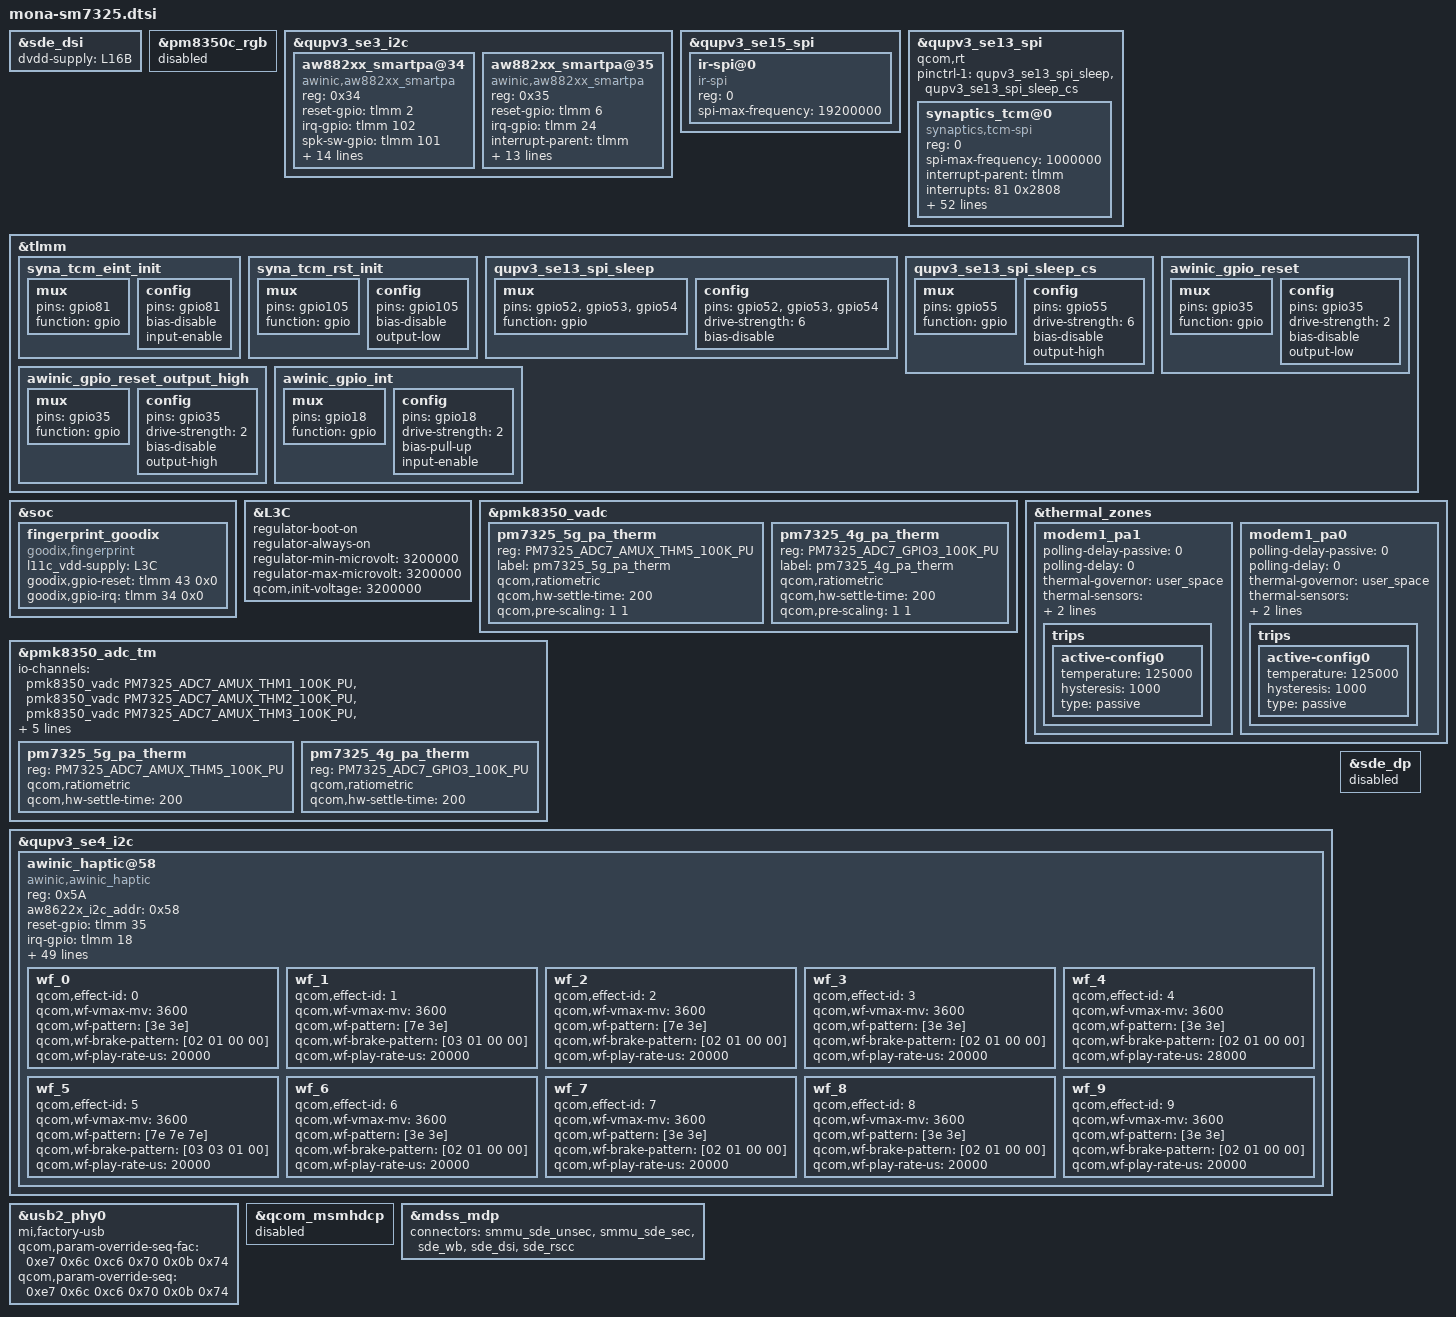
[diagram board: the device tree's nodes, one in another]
/*
this file is for attribution only of mona
And public attribution of xiaomi platforms
*/

#include "mona-pinctrl.dtsi"
#include "xiaomi-sm7325-common.dtsi"
#include "camera/mona-sm7325-camera-sensor.dtsi"
#include "mona-audio-overlay.dtsi"

&sde_dsi {
	dvdd-supply = <&L16B>;
};

&pm8350c_rgb {
	status = "disabled";
};

&qupv3_se3_i2c {
	status = "ok";

	/* TOP Smart PA */
	aw882xx_smartpa@34 {
		compatible = "awinic,aw882xx_smartpa";
		reg = <0x34>;
		reset-gpio = <&tlmm 2 0>;
		irq-gpio = <&tlmm 102 0>;
		spk-sw-gpio = <&tlmm 101 0>;
		interrupt-parent = <&tlmm>;
		interrupts = <102 0>;
		interrupt-names = "smartpa_irq";
		pinctrl-names = "default", "sleep";
		pinctrl-0 = <&top_smartpa_int_active>;
		pinctrl-1 = <&top_smartpa_int_suspend>;
		monitor-flag = <1>;
		dc-flag = <0>;
		aw-tx-topo-id = <0x1000ff01>;
		aw-rx-topo-id = <0x1000ff00>;
		aw-tx-port-id = <0x9001>;
		aw-rx-port-id = <0x9000>;
		aw-re-min = <4000>;
		aw-re-max= <9000>;
		aw-cali-mode = "aw_class";
		sound-channel = <0>;
		status = "ok";
	};

	/* BOT Smart PA */
	aw882xx_smartpa@35 {
		compatible = "awinic,aw882xx_smartpa";
		reg = <0x35>;
		reset-gpio = <&tlmm 6 0>;
		irq-gpio = <&tlmm 24 0>;
		interrupt-parent = <&tlmm>;
		interrupts = <24 0>;
		interrupt-names = "smartpa_irq";
		pinctrl-names = "default", "sleep";
		pinctrl-0 = <&bot_smartpa_int_active>;
		pinctrl-1 = <&bot_smartpa_int_suspend>;
		monitor-flag = <1>;
		dc-flag = <0>;
		aw-tx-topo-id = <0x1000ff01>;
		aw-rx-topo-id = <0x1000ff00>;
		aw-tx-port-id = <0x9001>;
		aw-rx-port-id = <0x9000>;
		aw-re-min = <4000>;
		aw-re-max= <9000>;
		aw-cali-mode = "aw_class";
		sound-channel = <1>;
		status = "ok";
	};
};

&qupv3_se15_spi {
	status = "ok";
	ir-spi@0 {
		compatible = "ir-spi";
		reg = <0>;
		spi-max-frequency = <19200000>;
		status = "ok";
	};
};

&qupv3_se13_spi {
	status = "ok";
	qcom,rt;
	pinctrl-1 = <&qupv3_se13_spi_sleep &qupv3_se13_spi_sleep_cs>;
	synaptics_tcm@0 {
		compatible = "synaptics,tcm-spi";
		reg = <0>;
		spi-max-frequency = <1000000>;
		interrupt-parent = <&tlmm>;
		interrupts = <81 0x2808>;
		synaptics,avdd-name = "avdd";
		avdd-supply = <&L7C>;
		synaptics,iovdd-name = "iovdd";
		iovdd-supply = <&L2C>;
		/*synaptics,bus-reg-name = "vdd";*/
		/*synaptics,pwr-reg-name = "avdd";*/
		synaptics,irq-gpio = <&tlmm 81 0x2808>;
		synaptics,reset-gpio = <&tlmm 105 0x00>;
		synaptics,irq-on-state = <0>;
		synaptics,spi-mode = <0>;
		synaptics,byte-delay-us = <0>;
		synaptics,block-delay-us = <0>;
		synaptics,power-delay-ms = <50>;
		synaptics,reset-delay-ms = <200>;
		synaptics,ubl-max-freq = <5000000>;
		synaptics,ubl-byte-delay-us = <20>;
		pinctrl-names = "default";
		pinctrl-0 = <&syna_tcm_eint_init &syna_tcm_rst_init>;
		synaptics,game-mode-array =
				<1 0 0 0 0>;  /* MAX MIN DEF SET GET	*/
		synaptics,active-mode-array =
				<1 0 0 0 0>;  /* MAX MIN DEF SET GET	*/
		synaptics,up-threshold-array =
				<3 0 3 3 3>;  /* MAX MIN DEF SET GET	*/
		synaptics,tolerance-array =
				<3 0 3 3 3>;  /* MAX MIN DEF SET GET	*/
		synaptics,edge-filter-array =
				<3 0 2 2 2>;  /* MAX MIN DEF SET GET	*/
		synaptics,panel-orien-array =
				<3 0 0 0 0>;  /* MAX MIN DEF SET GET	*/
		synaptics,report-rate-array =
				<3 0 0 0 0>;  /* MAX MIN DEF SET GET	*/
		synaptics,cornerfilter-area-step-array = <0 100 170 250>; /* step 0 to step 3 */
		synaptics,cornerzone-filter-hor1-array =
			/* B0:Type, B1:pos, B2:x0, B3:y0, B4:x1, B5:y1, B6:reserved, B7: reserved */
				<0 0 0 0 170 170 0 0>,
				<0 1 0 0 0 0 0 0>,
				<0 2 0 2229 170 2399 0 0>,
				<0 3 0 0 0 0 0 0>;
		synaptics,cornerzone-filter-hor2-array =
			/* B0:Type, B1:pos, B2:x0, B3:y0, B4:x1, B5:y1, B6:reserved, B7: reserved */
				<0 0 0 0 0 0 0 0>,
				<0 1 909 0 1079 170 0 0>,
				<0 2 0 0 0 0 0 0>,
				<0 3 909 2229 1079 2399 0 0>;
		synaptics,cornerzone-filter-ver-array =
			/* B0:Type, B1:pos, B2:x0, B3:y0, B4:x1, B5:y1, B6:reserved, B7: reserved */
				<0 0 0 0 0 0 0 0>,
				<0 1 0 0 0 0 0 0>,
				<0 2 0 2099 150 2399 0 0>,
				<0 3 929 2099 1079 2399 0 0>;
		synaptics,deadzone-filter-hor-array =
			/* B0:Type, B1:pos, B2:x0, B3:y0, B4:x1, B5:y1, B6:reserved, B7: reserved */
				<2 0 0 0 1079 5 0 0>,
				<2 1 0 2394 1079 2399 0 0>,
				<2 2 0 0 0 0 0 0>,
				<2 3 0 0 0 0 0 0>;
		synaptics,deadzone-filter-ver-array =
			/* B0:Type, B1:pos, B2:x0, B3:y0, B4:x1, B5:y1, B6:reserved, B7: reserved */
				<2 0 0 0 0 0 0 0>,
				<2 1 0 0 0 0 0 0>,
				<2 2 0 0 5 2399 0 0>,
				<2 3 1074 0 1079 2399 0 0>;
		synaptics,edgezone-filter-hor-array =
			/* B0:Type, B1:pos, B2:x0, B3:y0, B4:x1, B5:y1, B6:reserved, B7: reserved */
				<1 0 0 0 1079 40 0 0>,
				<1 1 0 2359 1079 2399 0 0>,
				<1 2 0 0 40 2399 0 0>,
				<1 3 1039 0 1079 2399 0 0>;
		synaptics,edgezone-filter-ver-array =
			/* B0:Type, B1:pos, B2:x0, B3:y0, B4:x1, B5:y1, B6:reserved, B7: reserved */
				<1 0 0 0 0 0 0 0>,
				<1 1 0 0 0 0 0 0>,
				<1 2 0 0 40 2399 0 0>,
				<1 3 1039 0 1079 2399 0 0>;
		synaptics,panel-display-resolution = <1079 2399>;  /* X  Y*/
	};
};

&tlmm {
	syna_tcm_eint_init: syna_tcm_eint_init {
		mux {
			/* GPIO 81 Interrupt */
			pins = "gpio81";
			function = "gpio";
		};

		config {
			pins = "gpio81";
			bias-disable;
			input-enable;
		};
	};

	syna_tcm_rst_init: syna_tcm_rst_init {
		mux {
			/* GPIO 105 Interrupt */
			pins = "gpio105";
			function = "gpio";
		};

		config {
			pins = "gpio105";
			bias-disable;
			output-low;
		};
	};

	qupv3_se13_spi_sleep: qupv3_se13_spi_sleep {
		mux {
			pins = "gpio52", "gpio53",
					"gpio54";
			function = "gpio";
		};

		config {
			pins = "gpio52", "gpio53",
					"gpio54";
			drive-strength = <6>;
			bias-disable;
		};
	};

	qupv3_se13_spi_sleep_cs: qupv3_se13_spi_sleep_cs {
		mux {
			pins = "gpio55";
			function = "gpio";
		};

		config {
			pins = "gpio55";
			drive-strength = <6>;
			bias-disable;
			output-high;
		};
	};
};

&soc {
	fingerprint_goodix {
		compatible = "goodix,fingerprint";
		l11c_vdd-supply = <&L3C>;
		goodix,gpio-reset = <&tlmm 43 0x0>;
		goodix,gpio-irq = <&tlmm 34 0x0>;
		status = "ok";
	};
};

&L3C {
	regulator-boot-on;
	regulator-always-on;
	regulator-min-microvolt = <3200000>;
	regulator-max-microvolt = <3200000>;
	qcom,init-voltage = <3200000>;
};


&pmk8350_vadc {
	pm7325_5g_pa_therm {
		reg = <PM7325_ADC7_AMUX_THM5_100K_PU>;
		label = "pm7325_5g_pa_therm";
		qcom,ratiometric;
		qcom,hw-settle-time = <200>;
		qcom,pre-scaling = <1 1>;
        };
	pm7325_4g_pa_therm {
		reg = <PM7325_ADC7_GPIO3_100K_PU>;
                label = "pm7325_4g_pa_therm";
		qcom,ratiometric;
		qcom,hw-settle-time = <200>;
		qcom,pre-scaling = <1 1>;
	};
};

&pmk8350_adc_tm {
	io-channels = <&pmk8350_vadc PM7325_ADC7_AMUX_THM1_100K_PU>,
			<&pmk8350_vadc PM7325_ADC7_AMUX_THM2_100K_PU>,
			<&pmk8350_vadc PM7325_ADC7_AMUX_THM3_100K_PU>,
			<&pmk8350_vadc PM7325_ADC7_AMUX_THM4_100K_PU>,
			<&pmk8350_vadc PMK8350_ADC7_AMUX_THM1_100K_PU>,
                        <&pmk8350_vadc PM7325B_ADC7_GPIO2_100K_PU>,
                        <&pmk8350_vadc PM7325_ADC7_AMUX_THM5_100K_PU>,
                        <&pmk8350_vadc PM7325_ADC7_GPIO3_100K_PU>;
	pm7325_5g_pa_therm {
		reg = <PM7325_ADC7_AMUX_THM5_100K_PU>;
		qcom,ratiometric;
		qcom,hw-settle-time = <200>;
	};
	pm7325_4g_pa_therm {
		reg = <PM7325_ADC7_GPIO3_100K_PU>;
		qcom,ratiometric;
		qcom,hw-settle-time = <200>;
	};
};

&thermal_zones {
	modem1_pa1 {
		polling-delay-passive = <0>;
		polling-delay = <0>;
		thermal-governor = "user_space";
		thermal-sensors = <&pmk8350_adc_tm PM7325_ADC7_AMUX_THM5_100K_PU>;
		wake-capable-sensor;
		trips {
			active-config0 {
				temperature = <125000>;
				hysteresis = <1000>;
				type = "passive";
			};
		};
	};

	modem1_pa0 {
		polling-delay-passive = <0>;
		polling-delay = <0>;
		thermal-governor = "user_space";
		thermal-sensors = <&pmk8350_adc_tm PM7325_ADC7_GPIO3_100K_PU>;
		wake-capable-sensor;
		trips {
			active-config0 {
				temperature = <125000>;
				hysteresis = <1000>;
				type = "passive";
			};
		};
	};
};
&qupv3_se4_i2c {
     status = "ok";
     awinic_haptic@58 {
		compatible = "awinic,awinic_haptic";
		reg = <0x5A>;
		aw8622x_i2c_addr = < 0x58 >;
		reset-gpio = <&tlmm 35 0>;
		irq-gpio = <&tlmm 18 0>;
		pinctrl-names = "awinic_reset_reset","awinic_reset_active","awinic_interrupt_active";
		pinctrl-0 = <&awinic_gpio_reset>;
		pinctrl-1 = <&awinic_gpio_reset_output_high>;
		pinctrl-2 = <&awinic_gpio_int>;
		/*---------------------aw8624_dts_info---------------------*/
		aw8624_vib_f0_pre = < 2050 >;
		aw8624_vib_f0_cali_percen = < 7 >;
		aw8624_vib_cont_drv_lev = < 106 >;
		aw8624_vib_cont_drv_lvl_ov = < 155 >;
		aw8624_vib_cont_td = < 0xF06C >;
		aw8624_vib_cont_zc_thr = < 0x08F8 >;
		aw8624_vib_cont_num_brk = < 3 >;
		aw8624_vib_f0_coeff = < 260 >; /*Don't modify it*/
		aw8624_vib_duration_time = < 15 60 0 0 0 >;
		aw8624_vib_brake_ram_config = < 1 1 90 60 20 3 1 3 1 1 90 60 30 5 1 3 0 0 50 40 25 0 5 3 >;
		aw8624_vib_brake_cont_config = < 1 1 90 42 20 5 2 2 0 0 0 0 0 0 0 0 0 0 0 0 0 0 0 0 >;
		aw8624_vib_f0_trace_parameter = < 9 5 1 15 >;
		aw8624_vib_bemf_config = < 0 8 3 0xf8 >;
		aw8624_vib_sw_brake = < 0x2c >;
		aw8624_vib_wavseq = < 0 1 1 2 0 0 0 0 0 0 0 0 0 0 0 0 >; /*wavseq1-seq8 0x07-0x0E*/
		aw8624_vib_wavloop = < 0 6 1 15 0 0 0 0 0 0>;/*loop1-mainloog 0x0f-0x13*/
		aw8624_vib_td_brake = < 42720 42720 42720 >; /*level0 level1 level2*/
		aw8624_vib_tset = < 0x11 >;
		aw8624_vib_func_parameter1 = < 1 >;
		aw8624_vib_gain_flag = < 1 >;
		aw8624_vib_r_spare = < 0x68 >;
		aw8624_vib_bstdbg = < 0x30 0xeb 0xd4 0 0 0 >;
		/*---------------------aw8622x_dts_info---------------------*/
		aw8622x_vib_mode = < 0 >; /* mode: RAM mode->0; CONT mode->1 */
		aw8622x_vib_f0_pre = < 2050 >;
		aw8622x_vib_f0_cali_percen = < 7 >;
		aw8622x_vib_cont_drv1_lvl = < 0x7F >;
		aw8622x_vib_cont_drv2_lvl = < 0x36 >;
		aw8622x_vib_cont_brk_time = < 0x06 >;
		aw8622x_vib_cont_tset = < 0x06 >;
		aw8622x_vib_cont_bemf_set = < 0x02 >;
		aw8622x_vib_cont_drv_width = < 0x6A >;
		aw8622x_vib_cont_wait_num = < 0x06 >;
		aw8622x_vib_cont_brk_gain = < 0x08 >;
		aw8622x_vib_cont_drv1_time = < 0x04 >;
		aw8622x_vib_cont_drv2_time = < 0x14 >;
		aw8622x_vib_cont_track_margin = < 0x12 >;
		aw8622x_vib_sine_array = < 0x05 0xB2 0xFF 0xEF >; /* SIN_H SIN_L COS_H COS_L*/
		aw8622x_vib_d2s_gain = < 0x05 >;
		aw8622x_vib_prctmode = < 0x2D 0x3E 0x3F >;
		/*---------------------common_dts_info---------------------*/
		vib_effect_id_boundary = < 10 >;
		vib_effect_max = < 170 >;
		vib_rtp_time = < 20 20 20 20 20 20 20 20 20 30
				 40 50 60 70 80 90 100 110 120 130
				 140 150 160 170 180 190 200 210 220 230
				 240 250 260 270 280 290 300 310 320 330
				 20 20 20 20 20 20 20 20 20 20
				 20 20 20 20 20 20 20 20 20 20
				 20 20 20 20 20 20 20 20 20 20
				 20 20 20 20 20 20 20 20 20 20
				 20 20 20 20 20 20 20 20 20 20
				 20 20 20 20 20 20 20 20 20 20
				 20 20 20 20 20 20 20 20 20 20
				 20 20 20 20 20 20 20 20 20 20
				 20 20 20 20 20 20 20 20 20 20
				 20 20 20 20 20 20 20 20 20 20
				 20 20 20 20 20 20 20 20 20 20
				 20 20 20 20 20 20 20 20 20 20
				 20 20 20 20 20 20 20 20 20 20
				 20 20 20 20 20 >;
		status = "okay";
		wf_0 {
			//CLICK
			qcom,effect-id = <0>;
			qcom,wf-vmax-mv = <3600>;
			qcom,wf-pattern = [3e 3e];
			qcom,wf-brake-pattern = [02 01 00 00];
			qcom,wf-play-rate-us = <20000>;
		};
		wf_1 {
			//DOUBLE CLICK
			qcom,effect-id = <1>;
			qcom,wf-vmax-mv = <3600>;
			qcom,wf-pattern = [7e 3e];
			qcom,wf-brake-pattern = [03 01 00 00];
			qcom,wf-play-rate-us = <20000>;
		};
		wf_2 {
			//TICK
			qcom,effect-id = <2>;
			qcom,wf-vmax-mv = <3600>;
			qcom,wf-pattern = [7e 3e];
			qcom,wf-brake-pattern = [02 01 00 00];
			qcom,wf-play-rate-us = <20000>;
		};
		wf_3 {
			//THUD
			qcom,effect-id = <3>;
			qcom,wf-vmax-mv = <3600>;
			qcom,wf-pattern = [3e 3e];
			qcom,wf-brake-pattern = [02 01 00 00];
			qcom,wf-play-rate-us = <20000>;
		};
		wf_4 {
			//POP
			qcom,effect-id = <4>;
			qcom,wf-vmax-mv = <3600>;
			qcom,wf-pattern = [3e 3e];
			qcom,wf-brake-pattern = [02 01 00 00];
			qcom,wf-play-rate-us = <28000>;
		};
		wf_5 {
			//HEAVY CLICK
			qcom,effect-id = <5>;
			qcom,wf-vmax-mv = <3600>;
			qcom,wf-pattern = [7e 7e 7e];
			qcom,wf-brake-pattern = [03 03 01 00];
			qcom,wf-play-rate-us = <20000>;
		};
		wf_6 {
			//id 6
			qcom,effect-id = <6>;
			qcom,wf-vmax-mv = <3600>;
			qcom,wf-pattern = [3e 3e];
			qcom,wf-brake-pattern = [02 01 00 00];
			qcom,wf-play-rate-us = <20000>;
		};
		wf_7 {
			//id 7
			qcom,effect-id = <7>;
			qcom,wf-vmax-mv = <3600>;
			qcom,wf-pattern = [3e 3e];
			qcom,wf-brake-pattern = [02 01 00 00];
			qcom,wf-play-rate-us = <20000>;
		};
		wf_8 {
			//id 8
			qcom,effect-id = <8>;
			qcom,wf-vmax-mv = <3600>;
			qcom,wf-pattern = [3e 3e];
			qcom,wf-brake-pattern = [02 01 00 00];
			qcom,wf-play-rate-us = <20000>;
		};
		wf_9 {
			//id 9
			qcom,effect-id = <9>;
			qcom,wf-vmax-mv = <3600>;
			qcom,wf-pattern = [3e 3e];
			qcom,wf-brake-pattern = [02 01 00 00];
			qcom,wf-play-rate-us = <20000>;
		};
     };
};
&tlmm {
	/* AW86224_RESET_N */
	awinic_gpio_reset: awinic_gpio_reset {
		mux {
			pins = "gpio35";
		        function = "gpio";
		};

		config {
			pins = "gpio35";
			drive-strength = <2>;
			bias-disable;
			output-low;
		};
	};
	/* AW8624_RESET_N, state device active*/
	awinic_gpio_reset_output_high: awinic_gpio_reset_output_high {
		mux {
			pins = "gpio35";
			function = "gpio";
		};

		config {
			pins = "gpio35";
			drive-strength = <2>;
			bias-disable;
			output-high;
		};
	};
	/* AW86224_INTERRUPT_N */
	awinic_gpio_int: awinic_gpio_int {
		mux {
			pins = "gpio18";
			function = "gpio";
		};

		config {
			pins = "gpio18";
			drive-strength = <2>;
			bias-pull-up;
			input-enable;
		};
	};
};

&usb2_phy0 {
	mi,factory-usb;
	qcom,param-override-seq-fac =
		<0xe7 0x6c	/* override_x0 */
		0xc6 0x70	/* override_x1 */
		0x0b 0x74>;	/* override x2 */
	qcom,param-override-seq =
		<0xe7 0x6c	/* override_x0 */
		0xc6 0x70	/* override_x1 */
		0x0b 0x74>;	/* override x2 */
};

&sde_dp {
	status = "disabled";
};

&qcom_msmhdcp {
	status = "disabled";
};

&mdss_mdp {
	connectors = <&smmu_sde_unsec &smmu_sde_sec &sde_wb &sde_dsi
		&sde_rscc>;
};

